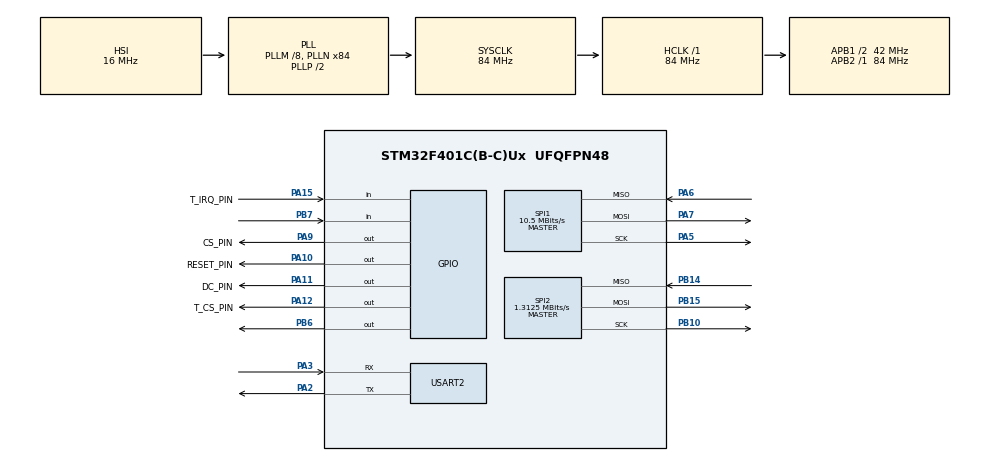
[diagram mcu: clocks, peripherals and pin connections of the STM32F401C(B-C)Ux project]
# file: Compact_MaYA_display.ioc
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Dma.Request0=SPI1_TX
Dma.Request1=USART2_RX
Dma.Request2=USART2_TX
Dma.SPI1_TX.0.Direction=DMA_MEMORY_TO_PERIPH
Dma.SPI1_TX.0.FIFOMode=DMA_FIFOMODE_DISABLE
Dma.SPI1_TX.0.Instance=DMA2_Stream3
Dma.SPI1_TX.0.MemDataAlignment=DMA_MDATAALIGN_BYTE
Dma.SPI1_TX.0.MemInc=DMA_MINC_ENABLE
Dma.SPI1_TX.0.Mode=DMA_NORMAL
Dma.SPI1_TX.0.PeriphDataAlignment=DMA_PDATAALIGN_BYTE
Dma.SPI1_TX.0.PeriphInc=DMA_PINC_DISABLE
Dma.SPI1_TX.0.Priority=DMA_PRIORITY_LOW
Dma.USART2_RX.1.Direction=DMA_PERIPH_TO_MEMORY
Dma.USART2_RX.1.FIFOMode=DMA_FIFOMODE_DISABLE
Dma.USART2_RX.1.Instance=DMA1_Stream5
Dma.USART2_RX.1.MemDataAlignment=DMA_MDATAALIGN_BYTE
Dma.USART2_RX.1.MemInc=DMA_MINC_ENABLE
Dma.USART2_RX.1.Mode=DMA_NORMAL
Dma.USART2_RX.1.PeriphDataAlignment=DMA_PDATAALIGN_BYTE
Dma.USART2_RX.1.PeriphInc=DMA_PINC_DISABLE
Dma.USART2_RX.1.Priority=DMA_PRIORITY_LOW
Dma.USART2_TX.2.Direction=DMA_MEMORY_TO_PERIPH
Dma.USART2_TX.2.FIFOMode=DMA_FIFOMODE_DISABLE
Dma.USART2_TX.2.Instance=DMA1_Stream6
Dma.USART2_TX.2.MemDataAlignment=DMA_MDATAALIGN_BYTE
Dma.USART2_TX.2.MemInc=DMA_MINC_ENABLE
Dma.USART2_TX.2.Mode=DMA_NORMAL
Dma.USART2_TX.2.PeriphDataAlignment=DMA_PDATAALIGN_BYTE
Dma.USART2_TX.2.PeriphInc=DMA_PINC_DISABLE
Dma.USART2_TX.2.Priority=DMA_PRIORITY_LOW
Mcu.Family=STM32F4
Mcu.Name=STM32F401C(B-C)Ux
Mcu.Package=UFQFPN48
NVIC.DMA1_Stream5_IRQn=true\:0\:0\:false\:false\:true\:false\:true\:true
NVIC.DMA1_Stream6_IRQn=true\:0\:0\:false\:false\:true\:false\:true\:true
NVIC.DMA2_Stream3_IRQn=true\:0\:0\:false\:false\:true\:false\:true\:true
NVIC.PriorityGroup=NVIC_PRIORITYGROUP_4
NVIC.USART2_IRQn=true\:0\:0\:false\:false\:true\:true\:true\:true
PA10.GPIO_Label=RESET_PIN
PA10.Signal=GPIO_Output
PA11.GPIO_Label=DC_PIN
PA11.Signal=GPIO_Output
PA12.GPIO_Label=T_CS_PIN
PA12.Signal=GPIO_Output
PA15.GPIO_Label=T_IRQ_PIN
PA15.Signal=GPIO_Input
PA2.Mode=Asynchronous
PA2.Signal=USART2_TX
PA3.Mode=Asynchronous
PA3.Signal=USART2_RX
PA5.Mode=Full_Duplex_Master
PA5.Signal=SPI1_SCK
PA6.Mode=Full_Duplex_Master
PA6.Signal=SPI1_MISO
PA7.Mode=Full_Duplex_Master
PA7.Signal=SPI1_MOSI
PA9.GPIO_Label=CS_PIN
PA9.Signal=GPIO_Output
PB10.Mode=Full_Duplex_Master
PB10.Signal=SPI2_SCK
PB14.Mode=Full_Duplex_Master
PB14.Signal=SPI2_MISO
PB15.Mode=Full_Duplex_Master
PB15.Signal=SPI2_MOSI
PB6.Signal=GPIO_Output
PB7.Signal=GPIO_Input
PH0\ -\ OSC_IN.Mode=HSE-External-Oscillator
PH0\ -\ OSC_IN.Signal=RCC_OSC_IN
PH1\ -\ OSC_OUT.Mode=HSE-External-Oscillator
PH1\ -\ OSC_OUT.Signal=RCC_OSC_OUT
ProjectManager.HeapSize=0x200
ProjectManager.StackSize=0x400
ProjectManager.TargetToolchain=STM32CubeIDE
RCC.48MHZClocksFreq_Value=42000000
RCC.AHBFreq_Value=84000000
RCC.APB1CLKDivider=RCC_HCLK_DIV2
RCC.APB1Freq_Value=42000000
RCC.APB1TimFreq_Value=84000000
RCC.APB2Freq_Value=84000000
RCC.APB2TimFreq_Value=84000000
RCC.CortexFreq_Value=84000000
RCC.HCLKFreq_Value=84000000
RCC.HSE_VALUE=25000000
RCC.HSI_VALUE=16000000
RCC.LSE_VALUE=32768
RCC.PLLM=8
RCC.PLLN=84
RCC.SYSCLKFreq_VALUE=84000000
RCC.SYSCLKSource=RCC_SYSCLKSOURCE_PLLCLK
RCC.VCOOutputFreq_Value=168000000
SPI1.BaudRatePrescaler=SPI_BAUDRATEPRESCALER_8
SPI1.CalculateBaudRate=10.5 MBits/s
SPI1.Direction=SPI_DIRECTION_2LINES
SPI1.Mode=SPI_MODE_MASTER
SPI1.VirtualType=VM_MASTER
SPI2.BaudRatePrescaler=SPI_BAUDRATEPRESCALER_32
SPI2.CalculateBaudRate=1.3125 MBits/s
SPI2.Direction=SPI_DIRECTION_2LINES
SPI2.Mode=SPI_MODE_MASTER
SPI2.VirtualType=VM_MASTER
STMicroelectronics.X-CUBE-TOUCHGFX.4.25.0.tgfx_block_size=2048
STMicroelectronics.X-CUBE-TOUCHGFX.4.25.0.tgfx_buffering_strategy=Partial
STMicroelectronics.X-CUBE-TOUCHGFX.4.25.0.tgfx_custom_height=240
STMicroelectronics.X-CUBE-TOUCHGFX.4.25.0.tgfx_custom_width=320
STMicroelectronics.X-CUBE-TOUCHGFX.4.25.0.tgfx_partialfb_transmit_strategy=Enabled
STMicroelectronics.X-CUBE-TOUCHGFX.4.25.0_IsPackSelfContextualization=true
USART2.VirtualMode=VM_ASYNC
VP_CRC_VS_CRC.Mode=CRC_Activate
board=custom

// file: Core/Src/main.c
/* USER CODE BEGIN Header */
/**
 ******************************************************************************
 * @file           : main.c
 * @brief          : Main program body
 ******************************************************************************
 * @attention
 *
 * Copyright (c) 2025 STMicroelectronics.
 * All rights reserved.
 *
 * This software is licensed under terms that can be found in the LICENSE file
 * in the root directory of this software component.
 * If no LICENSE file comes with this software, it is provided AS-IS.
 *
 ******************************************************************************
 */
/* USER CODE END Header */
#include "main.h"

/* USER CODE BEGIN Includes */
#include "ili9341_stm32_driver.h"
#include "ili9341_gfx.h"
#include "simpleDisplay.h"
#include "check_display_input.h"
#include "uart_message.h"
/* USER CODE END Includes */

CRC_HandleTypeDef hcrc;

SPI_HandleTypeDef hspi1;
SPI_HandleTypeDef hspi2;
DMA_HandleTypeDef hdma_spi1_tx;

UART_HandleTypeDef huart2;
DMA_HandleTypeDef hdma_usart2_rx;
DMA_HandleTypeDef hdma_usart2_tx;

void SystemClock_Config(void);
static void MX_GPIO_Init(void);
static void MX_DMA_Init(void);
static void MX_SPI1_Init(void);
static void MX_USART2_UART_Init(void);
static void MX_CRC_Init(void);
static void MX_SPI2_Init(void);

int main(void)
{

  /* MCU Configuration--------------------------------------------------------*/

  /* Reset of all peripherals, Initializes the Flash interface and the Systick. */
  HAL_Init();

  /* Configure the system clock */
  SystemClock_Config();

  /* Initialize all configured peripherals */
  MX_GPIO_Init();
  MX_DMA_Init();
  MX_SPI1_Init();
  MX_USART2_UART_Init();
  MX_CRC_Init();
  MX_SPI2_Init();
  /* USER CODE BEGIN 2 */
	pageSetup();
	firstPage();
	waitUntilTapAnywhere();
	sendDebugMessage("Hello World! from STM32Cube\n");
	menuPage();
	sendDebugMessage("Going to loop!\n");
  /* USER CODE END 2 */

  /* Infinite loop */
	while (1) {
		displayInputCheck();
	}
}

void SystemClock_Config(void)
{
  RCC_OscInitTypeDef RCC_OscInitStruct = {0};
  RCC_ClkInitTypeDef RCC_ClkInitStruct = {0};

  /** Configure the main internal regulator output voltage
  */
  __HAL_RCC_PWR_CLK_ENABLE();
  __HAL_PWR_VOLTAGESCALING_CONFIG(PWR_REGULATOR_VOLTAGE_SCALE2);

  /** Initializes the RCC Oscillators according to the specified parameters
  * in the RCC_OscInitTypeDef structure.
  */
  RCC_OscInitStruct.OscillatorType = RCC_OSCILLATORTYPE_HSI;
  RCC_OscInitStruct.HSIState = RCC_HSI_ON;
  RCC_OscInitStruct.HSICalibrationValue = RCC_HSICALIBRATION_DEFAULT;
  RCC_OscInitStruct.PLL.PLLState = RCC_PLL_ON;
  RCC_OscInitStruct.PLL.PLLSource = RCC_PLLSOURCE_HSI;
  RCC_OscInitStruct.PLL.PLLM = 8;
  RCC_OscInitStruct.PLL.PLLN = 84;
  RCC_OscInitStruct.PLL.PLLP = RCC_PLLP_DIV2;
  RCC_OscInitStruct.PLL.PLLQ = 4;
  if (HAL_RCC_OscConfig(&RCC_OscInitStruct) != HAL_OK)
  {
    Error_Handler();
  }

  /** Initializes the CPU, AHB and APB buses clocks
  */
  RCC_ClkInitStruct.ClockType = RCC_CLOCKTYPE_HCLK|RCC_CLOCKTYPE_SYSCLK
                              |RCC_CLOCKTYPE_PCLK1|RCC_CLOCKTYPE_PCLK2;
  RCC_ClkInitStruct.SYSCLKSource = RCC_SYSCLKSOURCE_PLLCLK;
  RCC_ClkInitStruct.AHBCLKDivider = RCC_SYSCLK_DIV1;
  RCC_ClkInitStruct.APB1CLKDivider = RCC_HCLK_DIV2;
  RCC_ClkInitStruct.APB2CLKDivider = RCC_HCLK_DIV1;

  if (HAL_RCC_ClockConfig(&RCC_ClkInitStruct, FLASH_LATENCY_2) != HAL_OK)
  {
    Error_Handler();
  }
}

static void MX_CRC_Init(void)
{

  hcrc.Instance = CRC;
  if (HAL_CRC_Init(&hcrc) != HAL_OK)
  {
    Error_Handler();
  }

}

static void MX_SPI1_Init(void)
{

  /* SPI1 parameter configuration*/
  hspi1.Instance = SPI1;
  hspi1.Init.Mode = SPI_MODE_MASTER;
  hspi1.Init.Direction = SPI_DIRECTION_2LINES;
  hspi1.Init.DataSize = SPI_DATASIZE_8BIT;
  hspi1.Init.CLKPolarity = SPI_POLARITY_LOW;
  hspi1.Init.CLKPhase = SPI_PHASE_1EDGE;
  hspi1.Init.NSS = SPI_NSS_SOFT;
  hspi1.Init.BaudRatePrescaler = SPI_BAUDRATEPRESCALER_8;
  hspi1.Init.FirstBit = SPI_FIRSTBIT_MSB;
  hspi1.Init.TIMode = SPI_TIMODE_DISABLE;
  hspi1.Init.CRCCalculation = SPI_CRCCALCULATION_DISABLE;
  hspi1.Init.CRCPolynomial = 10;
  if (HAL_SPI_Init(&hspi1) != HAL_OK)
  {
    Error_Handler();
  }

}

static void MX_SPI2_Init(void)
{

  /* SPI2 parameter configuration*/
  hspi2.Instance = SPI2;
  hspi2.Init.Mode = SPI_MODE_MASTER;
  hspi2.Init.Direction = SPI_DIRECTION_2LINES;
  hspi2.Init.DataSize = SPI_DATASIZE_8BIT;
  hspi2.Init.CLKPolarity = SPI_POLARITY_LOW;
  hspi2.Init.CLKPhase = SPI_PHASE_1EDGE;
  hspi2.Init.NSS = SPI_NSS_SOFT;
  hspi2.Init.BaudRatePrescaler = SPI_BAUDRATEPRESCALER_32;
  hspi2.Init.FirstBit = SPI_FIRSTBIT_MSB;
  hspi2.Init.TIMode = SPI_TIMODE_DISABLE;
  hspi2.Init.CRCCalculation = SPI_CRCCALCULATION_DISABLE;
  hspi2.Init.CRCPolynomial = 10;
  if (HAL_SPI_Init(&hspi2) != HAL_OK)
  {
    Error_Handler();
  }

}

static void MX_USART2_UART_Init(void)
{

  huart2.Instance = USART2;
  huart2.Init.BaudRate = 115200;
  huart2.Init.WordLength = UART_WORDLENGTH_8B;
  huart2.Init.StopBits = UART_STOPBITS_1;
  huart2.Init.Parity = UART_PARITY_NONE;
  huart2.Init.Mode = UART_MODE_TX_RX;
  huart2.Init.HwFlowCtl = UART_HWCONTROL_NONE;
  huart2.Init.OverSampling = UART_OVERSAMPLING_16;
  if (HAL_UART_Init(&huart2) != HAL_OK)
  {
    Error_Handler();
  }

}

static void MX_DMA_Init(void)
{

  /* DMA controller clock enable */
  __HAL_RCC_DMA2_CLK_ENABLE();
  __HAL_RCC_DMA1_CLK_ENABLE();

  /* DMA interrupt init */
  /* DMA1_Stream5_IRQn interrupt configuration */
  HAL_NVIC_SetPriority(DMA1_Stream5_IRQn, 0, 0);
  HAL_NVIC_EnableIRQ(DMA1_Stream5_IRQn);
  /* DMA1_Stream6_IRQn interrupt configuration */
  HAL_NVIC_SetPriority(DMA1_Stream6_IRQn, 0, 0);
  HAL_NVIC_EnableIRQ(DMA1_Stream6_IRQn);
  /* DMA2_Stream3_IRQn interrupt configuration */
  HAL_NVIC_SetPriority(DMA2_Stream3_IRQn, 0, 0);
  HAL_NVIC_EnableIRQ(DMA2_Stream3_IRQn);

}

static void MX_GPIO_Init(void)
{
  GPIO_InitTypeDef GPIO_InitStruct = {0};

  /* GPIO Ports Clock Enable */
  __HAL_RCC_GPIOH_CLK_ENABLE();
  __HAL_RCC_GPIOA_CLK_ENABLE();
  __HAL_RCC_GPIOB_CLK_ENABLE();

  /*Configure GPIO pin Output Level */
  HAL_GPIO_WritePin(GPIOA, CS_PIN_Pin|RESET_PIN_Pin|DC_PIN_Pin|T_CS_PIN_Pin, GPIO_PIN_RESET);

  /*Configure GPIO pin Output Level */
  HAL_GPIO_WritePin(GPIOB, GPIO_PIN_6, GPIO_PIN_RESET);

  /*Configure GPIO pins : CS_PIN_Pin RESET_PIN_Pin DC_PIN_Pin T_CS_PIN_Pin */
  GPIO_InitStruct.Pin = CS_PIN_Pin|RESET_PIN_Pin|DC_PIN_Pin|T_CS_PIN_Pin;
  GPIO_InitStruct.Mode = GPIO_MODE_OUTPUT_PP;
  GPIO_InitStruct.Pull = GPIO_NOPULL;
  GPIO_InitStruct.Speed = GPIO_SPEED_FREQ_LOW;
  HAL_GPIO_Init(GPIOA, &GPIO_InitStruct);

  /*Configure GPIO pin : T_IRQ_PIN_Pin */
  GPIO_InitStruct.Pin = T_IRQ_PIN_Pin;
  GPIO_InitStruct.Mode = GPIO_MODE_INPUT;
  GPIO_InitStruct.Pull = GPIO_NOPULL;
  HAL_GPIO_Init(T_IRQ_PIN_GPIO_Port, &GPIO_InitStruct);

  /*Configure GPIO pin : PB6 */
  GPIO_InitStruct.Pin = GPIO_PIN_6;
  GPIO_InitStruct.Mode = GPIO_MODE_OUTPUT_PP;
  GPIO_InitStruct.Pull = GPIO_NOPULL;
  GPIO_InitStruct.Speed = GPIO_SPEED_FREQ_LOW;
  HAL_GPIO_Init(GPIOB, &GPIO_InitStruct);

  /*Configure GPIO pin : PB7 */
  GPIO_InitStruct.Pin = GPIO_PIN_7;
  GPIO_InitStruct.Mode = GPIO_MODE_INPUT;
  GPIO_InitStruct.Pull = GPIO_NOPULL;
  HAL_GPIO_Init(GPIOB, &GPIO_InitStruct);

}

void Error_Handler(void)
{
	__disable_irq();
	while (1) {
	}
}
